# SPI register map
Vendor: Texas Instruments
Peripheral module from a debugger description file (folder ucd3138064A).
Registers are 32-bit, access not given, no defined reset value unless marked. A register's access mark holds for its fields unless they carry their own. Offsets are as the file gives them; lines under a group give offsets from that group; [hi:lo] are bit positions; {n}, {i} and the like mark numbered series; 'fields as' and 'values as' point back to an identical list; <NAME> marks a mode.

## SPI
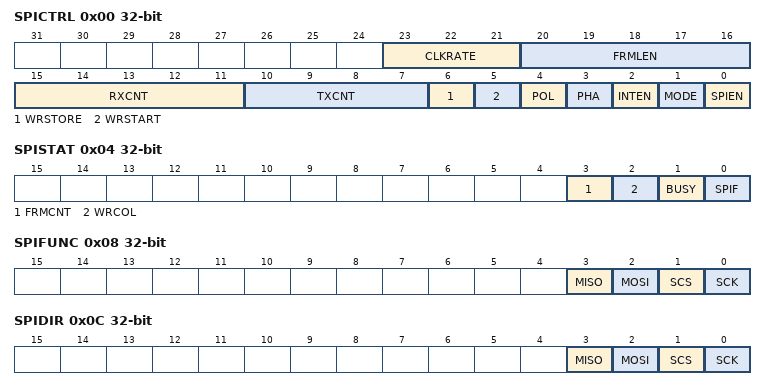
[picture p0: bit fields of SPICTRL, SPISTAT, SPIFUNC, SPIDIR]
0x00 SPICTRL
  [23:21] CLKRATE rw — Clock rate
  [20:16] FRMLEN rw — Frame Length
  [15:11] RXCNT rw
  [10:7] TXCNT rw
  [6] WRSTORE rw — Write Store Sel
  [5] WRSTART rw — Write Start Sel
  [4] POL rw — Polarity
  [3] PHA rw — Phase
  [2] INTEN rw
  [1] MODE rw
  [0] SPIEN rw — SPI Enable
0x04 SPISTAT
  [3] FRMCNT ro — Frame Count
  [2] WRCOL ro — Write Collision
  [1] BUSY ro — SPI Busy
  [0] SPIF ro — SPI Flag
0x08 SPIFUNC
  [3] MISO rw — MISO Pin
  [2] MOSI rw — MOSI Pin
  [1] SCS rw — SCS Pin
  [0] SCK rw
0x0C SPIDIR
  [3] MISO rw — MISO Pin
  [2] MOSI rw — MOSI Pin
  [1] SCS rw — SCS Pin
  [0] SCK rw — SCK Pin
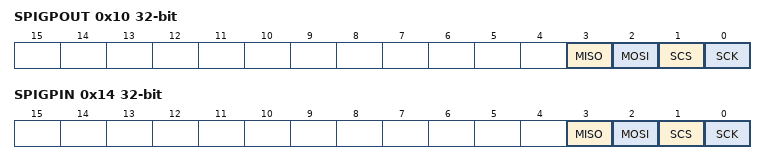
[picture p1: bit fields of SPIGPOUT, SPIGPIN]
0x10 SPIGPOUT
  fields as SPIDIR
0x14 SPIGPIN
  fields as SPIDIR
0x18 SPITX0 rw
  [31:0] DATA
0x1C SPITX1 rw
  [31:0] DATA
{0x20+4i} SPIRX{i} ro (i=0..3)
  [31:0] DATA
